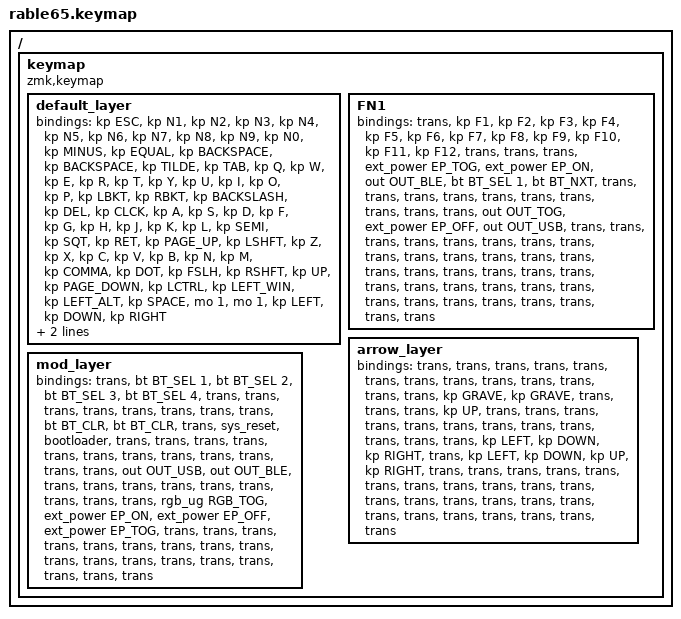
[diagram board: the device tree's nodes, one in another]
/*
 * Copyright (c) 2021 Nick Winans
 *
 * SPDX-License-Identifier: MIT
 */

#include <behaviors.dtsi>
#include <dt-bindings/zmk/bt.h>
#include <dt-bindings/zmk/ext_power.h>
#include <dt-bindings/zmk/keys.h>
#include <dt-bindings/zmk/outputs.h>
#include <dt-bindings/zmk/rgb.h>

/ {
    keymap {
        compatible = "zmk,keymap";

        default_layer {
            bindings = <
&kp ESC  &kp N1  &kp N2  &kp N3  &kp N4  &kp N5  &kp N6  &kp N7  &kp N8  &kp N9  &kp N0  &kp MINUS  &kp EQUAL  &kp BACKSPACE  &kp BACKSPACE  &kp TILDE  &kp TAB  &kp Q  &kp W  &kp E  &kp R  &kp T  &kp Y  &kp U  &kp I  &kp O  &kp P  &kp LBKT  &kp RBKT  &kp BACKSLASH  &kp DEL  &kp CLCK  &kp A  &kp S  &kp D  &kp F  &kp G  &kp H  &kp J  &kp K  &kp L  &kp SEMI  &kp SQT  &kp RET  &kp PAGE_UP  &kp LSHFT  &kp Z  &kp X  &kp C  &kp V  &kp B  &kp N  &kp M  &kp COMMA  &kp DOT  &kp FSLH  &kp RSHFT  &kp UP  &kp PAGE_DOWN  &kp LCTRL  &kp LEFT_WIN  &kp LEFT_ALT  &kp SPACE  &mo 1  &mo 1  &kp LEFT  &kp DOWN  &kp RIGHT
            >;

            sensor-bindings = <&inc_dec_kp C_VOLUME_UP C_VOLUME_DOWN>;
        };

        FN1 {
            bindings = <
&trans  &kp F1  &kp F2  &kp F3  &kp F4  &kp F5  &kp F6  &kp F7  &kp F8  &kp F9  &kp F10  &kp F11  &kp F12  &trans  &trans  &trans  &ext_power EP_TOG  &ext_power EP_ON  &out OUT_BLE  &bt BT_SEL 1  &bt BT_NXT  &trans  &trans  &trans  &trans  &trans  &trans  &trans  &trans  &trans  &trans  &out OUT_TOG  &ext_power EP_OFF  &out OUT_USB  &trans  &trans  &trans  &trans  &trans  &trans  &trans  &trans  &trans  &trans  &trans  &trans  &trans  &trans  &trans  &trans  &trans  &trans  &trans  &trans  &trans  &trans  &trans  &trans  &trans  &trans  &trans  &trans  &trans  &trans  &trans  &trans  &trans  &trans
            >;
        };

        arrow_layer {
            // ----------------------------------------------------------------------------------------------------------------
            // |        |    |     |     |     |     |     |     |     |     |     |     |     |     |     |   `~    |
            // |        |    |     |     |     |     |     |     |     |     |     |     |     |     |     |         |
            // |        |    |     |     |     |     |     |LEFT |DOWN |  UP |RIGHT|     |     |     |     |         |
            // |        |    |     |     |     |     |     |     |     |     |     |     |     |     |     |         |
            // |        |    |     |     |                                               |     |     |     |         |
            // ----------------------------------------------------------------------------------------------------------------

            bindings = <
&trans  &trans  &trans  &trans  &trans  &trans  &trans  &trans  &trans  &trans  &trans  &trans  &trans  &kp GRAVE  &kp GRAVE  &trans  &trans  &trans  &kp UP  &trans  &trans  &trans  &trans  &trans  &trans  &trans  &trans  &trans  &trans  &trans  &trans  &kp LEFT  &kp DOWN  &kp RIGHT  &trans  &kp LEFT  &kp DOWN  &kp UP  &kp RIGHT  &trans  &trans  &trans  &trans  &trans  &trans  &trans  &trans  &trans  &trans  &trans  &trans  &trans  &trans  &trans  &trans  &trans  &trans  &trans  &trans  &trans  &trans  &trans  &trans
            >;
        };

        mod_layer {
            // ----------------------------------------------------------------------------------------------------------------
            // |        |    | BT 1|BT 2 |BT 3 |BT 4 |     |     |     |     |     |     |     |     |BT CLR |         |
            // |        |    | RST | BOOT|     |     |     |     |     |     |     |     |     |     |       |         |
            // |        |    | USB | BLE |     |     |     |     |     |     |     |     |     |     |RGB TOG|         |
            // |        |    |EP_ON|EP_OFF|EP_TOG|     |     |     |     |     |     |     |     |     |       |         |
            // |        |    |     |     |                                               |     |     |       |         |
            // ----------------------------------------------------------------------------------------------------------------

            bindings = <
&trans  &bt BT_SEL 1  &bt BT_SEL 2  &bt BT_SEL 3  &bt BT_SEL 4  &trans  &trans  &trans  &trans  &trans  &trans  &trans  &trans  &bt BT_CLR  &bt BT_CLR  &trans  &sys_reset  &bootloader  &trans  &trans  &trans  &trans  &trans  &trans  &trans  &trans  &trans  &trans  &trans  &trans  &out OUT_USB  &out OUT_BLE  &trans  &trans  &trans  &trans  &trans  &trans  &trans  &trans  &trans  &rgb_ug RGB_TOG  &ext_power EP_ON  &ext_power EP_OFF  &ext_power EP_TOG  &trans  &trans  &trans  &trans  &trans  &trans  &trans  &trans  &trans  &trans  &trans  &trans  &trans  &trans  &trans  &trans  &trans  &trans
            >;
        };
    };
};
